# STM32U083 register map
File version: 0.2
CPU: CM0+ r0p1, little endian, MPU, no FPU, 4 interrupt priority bits
Registers are 32-bit, read-write, reset 0x0 unless marked. A register's access mark holds for its fields unless they carry their own. Offsets are from the block's base; [hi:lo] are bit positions; {n}, {i} and the like mark numbered series.

## CRC — CRC address block description
Base 0x40023000
0x00 CRC_DR reset 0xFFFFFFFF — CRC data register
  [31:0] DR — Data register bits This register is used to write new data to the CRC calculator. It holds the previous CRC calculation result when it is read. If the data size is less than 32 bits, the least significant bits are used to write/read the correct value.
0x04 CRC_IDR — CRC independent data register
  [31:0] IDR — General-purpose 32-bit data register bits These bits can be used as a temporary storage location for four bytes. This register is not affected by CRC resets generated by the RESET bit in the CRC_CR register
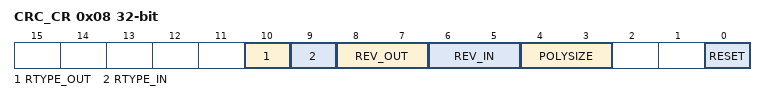
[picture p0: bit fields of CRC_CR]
0x08 CRC_CR — CRC control register
  [10] RTYPE_OUT — Reverse type output This bit controls the reversal granularity of the output data.
    0=Bit level output; 1=Byte or half-word level output
  [9] RTYPE_IN — Reverse type input This bit controls the reversal granularity of the input data.
    0=Bit level input; 1=Byte or half-word level input
  [8:7] REV_OUT — Reverse output data This bitfield controls the reversal of the bit order of the output data.
    0=Bit order not affected (RTYPE_OUT1=10 or 1); 1=Bit-reversed output format (RTYPE_OUT1=10) or half-word reversal done by word (RTYPE_OUT1=11); 2=Bit order not affected (RTYPE_OUT1=10) or byte reversal done by word (RTYPE_OUT1=11); 3=Bit order not affected (RTYPE_OUT1=10 or 1)
  [6:5] REV_IN — Reverse input data This bitfield controls the reversal of the bit order of the input data
    0=Bit order not affected (RTYPE_IN1=10 or 1); 1=Bit reversal done by byte (RTYPE_IN1=10) or half-word reversal done by word (RTYPE_IN1=11); 2=Bit reversal done by half-word (RTYPE_IN1=10) or byte reversal done by word (RTYPE_IN1=11); 3=Bit reversal done by word (RTYPE_IN1=10) or bit order is not affected (RTYPE_IN1=11)
  [4:3] POLYSIZE — Polynomial size These bits control the size of the polynomial.
    0=32 bit polynomial; 1=16 bit polynomial; 2=8 bit polynomial; 3=7 bit polynomial
  [0] RESET — RESET bit This bit is set by software to reset the CRC calculation unit and set the data register to the value stored in the CRC_INIT register. This bit can only be set, it is automatically cleared by hardware
0x10 CRC_INIT reset 0xFFFFFFFF — CRC initial value
  [31:0] CRC_INIT — Programmable initial CRC value This register is used to write the CRC initial value.
0x14 CRC_POL reset 0x4C11DB7 — CRC polynomial
  [31:0] POL — Programmable polynomial This register is used to write the coefficients of the polynomial to be used for CRC calculation. If the polynomial size is less than 32 bits, the least significant bits have to be used to program the correct value.

## DMAMUX — DMAMUX address block description
Base 0x40020800
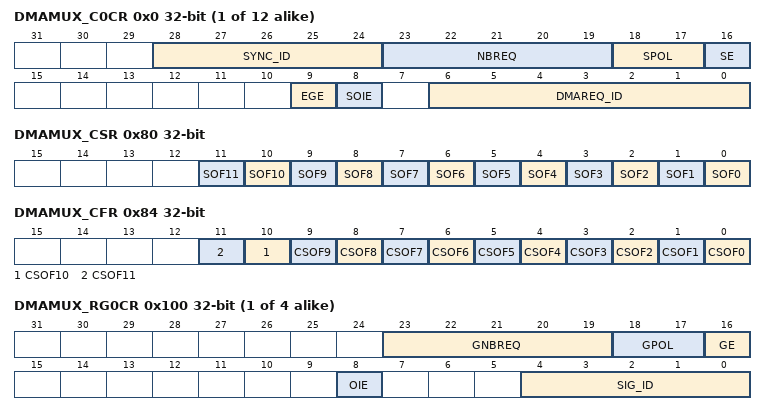
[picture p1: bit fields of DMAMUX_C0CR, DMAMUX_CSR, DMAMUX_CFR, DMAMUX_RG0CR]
{0x0+4i} DMAMUX_C{i}CR (i=0..11) — DMAMUX request line multiplexer channel {i} configuration register
  [28:24] SYNC_ID — Synchronization identification Selects the synchronization input (see Table137: DMAMUX: assignment of synchronization inputs to resources).
  [23:19] NBREQ — Number of DMA requests minus 1 to forward Defines the number of DMA requests to forward to the DMA controller after a synchronization event, and/or the number of DMA requests before an output event is generated. This field must only be written when both SE and EGE bits are low.
  [18:17] SPOL — Synchronization polarity Defines the edge polarity of the selected synchronization input:
    0=No event (no synchronization, no detection); 1=Rising edge; 2=Falling edge; 3=Rising and falling edges
  [16] SE — Synchronization enable
    0=Synchronization disabled; 1=Synchronization enabled
  [9] EGE — Event generation enable
    0=Event generation disabled; 1=Event generation enabled
  [8] SOIE — Synchronization overrun interrupt enable
    0=Interrupt disabled; 1=Interrupt enabled
  [6:0] DMAREQ_ID — DMA request identification Selects the input DMA request. See the DMAMUX table about assignments of multiplexer inputs to resources.
0x80 DMAMUX_CSR ro — DMAMUX request line multiplexer interrupt channel status register
  [n] SOF{n} (n=0..11) — Synchronization overrun event flag The flag is set when a synchronization event occurs on a DMA request line multiplexer channel x, while the DMA request counter value is lower than NBREQ. The flag is cleared by writing 1 to the corresponding CSOFx bit in DMAMUX_CFR register.
0x84 DMAMUX_CFR wo — DMAMUX request line multiplexer interrupt clear flag register
  [n] CSOF{n} (n=0..11) — Clear synchronization overrun event flag Writing 1 in each bit clears the corresponding overrun flag SOFx in the DMAMUX_CSR register.
{0x100+4i} DMAMUX_RG{i}CR (i=0..3) — DMAMUX request generator channel {i} configuration register
  [23:19] GNBREQ — Number of DMA requests to be generated (minus 1) Defines the number of DMA requests to be generated after a trigger event. The actual number of generated DMA requests is GNBREQ +1. Note: This field must be written only when GE bit is disabled.
  [18:17] GPOL — DMA request generator trigger polarity Defines the edge polarity of the selected trigger input
    0=No event, i.e. no trigger detection nor generation.; 1=Rising edge; 2=Falling edge; 3=Rising and falling edges
  [16] GE — DMA request generator channel x enable
    0=DMA request generator channel x disabled; 1=DMA request generator channel x enabled
  [8] OIE — Trigger overrun interrupt enable
    0=Interrupt on a trigger overrun event occurrence is disabled; 1=Interrupt on a trigger overrun event occurrence is enabled
  [4:0] SIG_ID — Signal identification Selects the DMA request trigger input used for the channel x of the DMA request generator
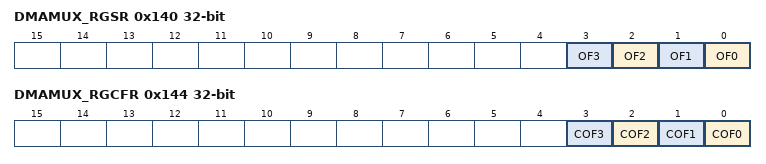
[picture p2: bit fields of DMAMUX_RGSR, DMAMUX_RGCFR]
0x140 DMAMUX_RGSR ro — DMAMUX request generator interrupt status register
  [n] OF{n} (n=0..3) — Trigger overrun event flag The flag is set when a new trigger event occurs on DMA request generator channel x, before the request counter underrun (the internal request counter programmed via the GNBREQ field of the DMAMUX_RGxCR register). The flag is cleared by writing 1 to the corresponding COFx bit in the DMAMUX_RGCFR register.
0x144 DMAMUX_RGCFR wo — DMAMUX request generator interrupt clear flag register
  [n] COF{n} (n=0..3) — Clear trigger overrun event flag Writing 1 in each bit clears the corresponding overrun flag OFx in the DMAMUX_RGSR register.
